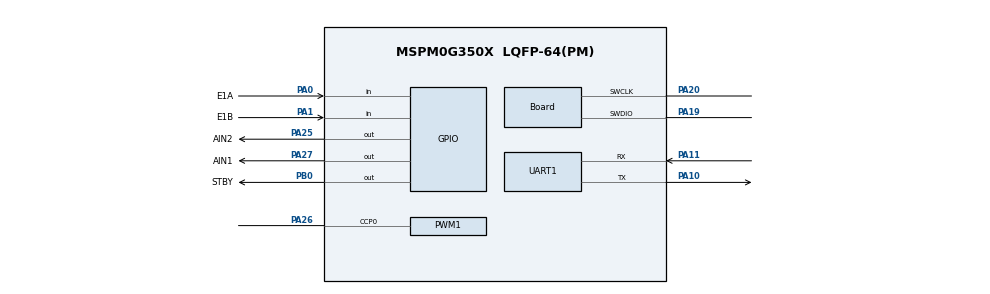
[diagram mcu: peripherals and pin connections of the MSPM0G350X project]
/**
 * @cliArgs --device "MSPM0G350X" --part "Default" --package "LQFP-64(PM)" --product "mspm0_sdk@2.04.00.06"
 * @versions {"tool":"1.23.1+4034"}
 */

/**
 * Import the modules used in this configuration.
 */
const GPIO   = scripting.addModule("/ti/driverlib/GPIO", {}, false);
const GPIO1  = GPIO.addInstance();
const GPIO2  = GPIO.addInstance();
const PWM    = scripting.addModule("/ti/driverlib/PWM", {}, false);
const PWM1   = PWM.addInstance();
const SYSCTL = scripting.addModule("/ti/driverlib/SYSCTL");
const TIMER  = scripting.addModule("/ti/driverlib/TIMER", {}, false);
const TIMER1 = TIMER.addInstance();
const UART   = scripting.addModule("/ti/driverlib/UART", {}, false);
const UART1  = UART.addInstance();

/**
 * Write custom configuration values to the imported modules.
 */
const gate7  = system.clockTree["MFCLKGATE"];
gate7.enable = true;

GPIO1.$name                               = "GPIO_ENCODER";
GPIO1.associatedPins.create(2);
GPIO1.associatedPins[0].$name             = "E1A";
GPIO1.associatedPins[0].direction         = "INPUT";
GPIO1.associatedPins[0].interruptEn       = true;
GPIO1.associatedPins[0].interruptPriority = "0";
GPIO1.associatedPins[0].polarity          = "RISE";
GPIO1.associatedPins[0].pin.$assign       = "PA0";
GPIO1.associatedPins[1].$name             = "E1B";
GPIO1.associatedPins[1].direction         = "INPUT";
GPIO1.associatedPins[1].interruptEn       = true;
GPIO1.associatedPins[1].interruptPriority = "0";
GPIO1.associatedPins[1].polarity          = "RISE";
GPIO1.associatedPins[1].pin.$assign       = "PA1";

const Board                       = scripting.addModule("/ti/driverlib/Board", {}, false);
Board.peripheral.$assign          = "DEBUGSS";
Board.peripheral.swclkPin.$assign = "PA20";
Board.peripheral.swdioPin.$assign = "PA19";

GPIO2.$name                         = "GPIO_TB6612";
GPIO2.associatedPins.create(3);
GPIO2.associatedPins[0].$name       = "AIN1";
GPIO2.associatedPins[0].pin.$assign = "PA27";
GPIO2.associatedPins[1].$name       = "AIN2";
GPIO2.associatedPins[1].pin.$assign = "PA25";
GPIO2.associatedPins[2].$name       = "STBY";
GPIO2.associatedPins[2].pin.$assign = "PB0";

PWM1.$name                              = "PWMA";
PWM1.ccIndex                            = [0];
PWM1.clockDivider                       = 8;
PWM1.clockPrescale                      = 4;
PWM1.timerCount                         = 100;
PWM1.PWM_CHANNEL_0.$name                = "ti_driverlib_pwm_PWMTimerCC0";
PWM1.ccp0PinConfig.direction            = scripting.forceWrite("OUTPUT");
PWM1.ccp0PinConfig.hideOutputInversion  = scripting.forceWrite(false);
PWM1.ccp0PinConfig.onlyInternalResistor = scripting.forceWrite(false);
PWM1.ccp0PinConfig.passedPeripheralType = scripting.forceWrite("Digital");
PWM1.ccp0PinConfig.$name                = "ti_driverlib_gpio_GPIOPinGeneric2";
PWM1.peripheral.$assign                 = "TIMG8";
PWM1.peripheral.ccp0Pin.$assign         = "PA26";

SYSCTL.forceDefaultClkConfig = true;
SYSCTL.clockTreeEn           = true;

TIMER1.$name              = "TIMER_TICK";
TIMER1.timerPeriod        = "20 ms";
TIMER1.timerClkDiv        = 8;
TIMER1.timerClkPrescale   = 4;
TIMER1.timerMode          = "PERIODIC";
TIMER1.timerStartTimer    = true;
TIMER1.interrupts         = ["ZERO"];
TIMER1.interruptPriority  = "3";
TIMER1.peripheral.$assign = "TIMG0";

UART1.$name                    = "UART_0";
UART1.uartClkSrc               = "MFCLK";
UART1.enabledInterrupts        = ["RX"];
UART1.peripheral.$assign       = "UART0";
UART1.peripheral.rxPin.$assign = "PA11";
UART1.peripheral.txPin.$assign = "PA10";
UART1.txPinConfig.$name        = "ti_driverlib_gpio_GPIOPinGeneric0";
UART1.rxPinConfig.$name        = "ti_driverlib_gpio_GPIOPinGeneric1";

const ProjectConfig              = scripting.addModule("/ti/project_config/ProjectConfig", {}, false);
ProjectConfig.migrationCondition = true;
